# R7FA8D1BH register map
Vendor: Renesas; Series: RA8; File version: 1.2
CPU: CM85 r0p0, little endian, MPU, FPU, VTOR, 4 interrupt priority bits
Registers are 32-bit, read-write, reset 0x0 unless marked. A register's access mark holds for its fields unless they carry their own. Offsets are from the block's base; [hi:lo] are bit positions; {n}, {i} and the like mark numbered series; 'fields as' and 'values as' point back to an identical list.

## I3C (part 1 of 4) — I2C I3C unified IP
Base 0x4035F000
Same registers: I3C_NS 0x5035F000
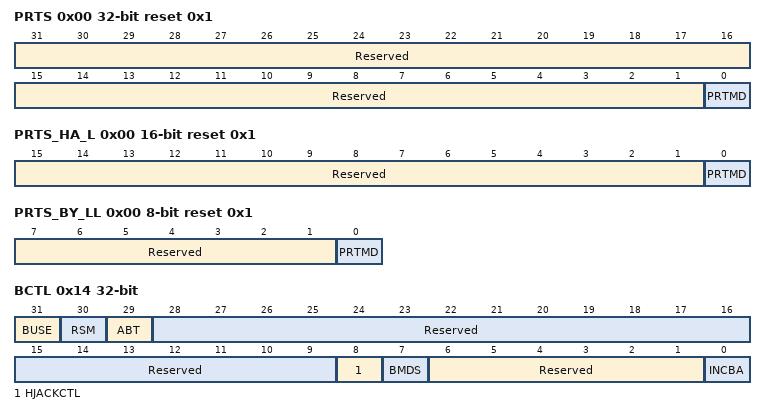
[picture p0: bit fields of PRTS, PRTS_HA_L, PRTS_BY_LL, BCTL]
0x00 PRTS reset 0x1 — Protocol Selection Register
  [31:1] Reserved — These bits are read as 0000000000000000000000000000000. The write value should be 0000000000000000000000000000000.
  [0] PRTMD — Protocol Mode.
    0=I3C Protocol mode; 1=I2C Protocol mode
0x00 PRTS_HA_L 16-bit reset 0x1 — Protocol Selection Register
  [15:1] Reserved — These bits are read as 000000000000000. The write value should be 000000000000000.
  [0] PRTMD — Protocol Mode.
    0=I3C Protocol mode; 1=I2C Protocol mode
0x00 PRTS_BY_LL 8-bit reset 0x1 — Protocol Selection Register
  [7:1] Reserved — These bits are read as 0000000. The write value should be 0000000.
  [0] PRTMD — Protocol Mode.
    0=I3C Protocol mode; 1=I2C Protocol mode
0x14 BCTL — Bus Control Register
  [31] BUSE read-modifies — Bus Enable
    0=This IP bus operation is Disabled; 1=This IP bus operation is Enabled
  [30] RSM write-1-clears read-modifies — Resume Values when read:
    0=This IP is Running; 1=This IP is Suspended (RW1C)
  [29] ABT — Abort
    0=This IP is Running; 1=This IP has Aborted a transfer
  [28:9] Reserved — These bits are read as 00000000000000000000. The write value should be 00000000000000000000.
  [8] HJACKCTL — Hot-Join Acknowledge Control
    0=ACK the Hot-Join request; 1=NACK and send broadcast CCC to disable Hot-Join
  [7] BMDS — Bus Mode Selection
    0=Legacy inclusive Bus mode disabled; 1=Legacy inclusive (mix) Bus mode enabled
  [6:1] Reserved — These bits are read as 000000. The write value should be 000000.
  [0] INCBA — Include I3C Broadcast Address
    0=Do not include I3C Broadcast Address for Private Transfers; 1=Include I3C Broadcast Address for Private Transfers
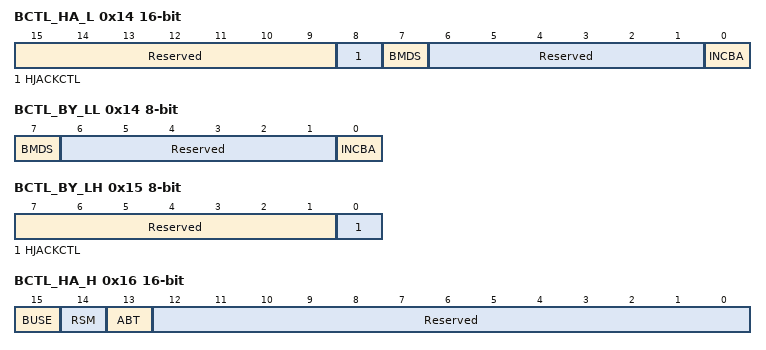
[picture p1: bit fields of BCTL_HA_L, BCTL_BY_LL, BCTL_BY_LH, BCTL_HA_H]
0x14 BCTL_HA_L 16-bit — Bus Control Register
  [15:9] Reserved — These bits are read as 0000000. The write value should be 0000000.
  [8] HJACKCTL — Hot-Join Acknowledge Control
    values as BCTL.HJACKCTL
  [7] BMDS — Bus Mode Selection
    values as BCTL.BMDS
  [6:1] Reserved — These bits are read as 000000. The write value should be 000000.
  [0] INCBA — Include I3C Broadcast Address
    values as BCTL.INCBA
0x14 BCTL_BY_LL 8-bit — Bus Control Register
  [7] BMDS — Bus Mode Selection
    values as BCTL.BMDS
  [6:1] Reserved — These bits are read as 000000. The write value should be 000000.
  [0] INCBA — Include I3C Broadcast Address
    values as BCTL.INCBA
0x15 BCTL_BY_LH 8-bit — Bus Control Register
  [7:1] Reserved — These bits are read as 0000000. The write value should be 0000000.
  [0] HJACKCTL — Hot-Join Acknowledge Control
    values as BCTL.HJACKCTL
0x16 BCTL_HA_H 16-bit — Bus Control Register
  [15] BUSE read-modifies — Bus Enable
    values as BCTL.BUSE
  [14] RSM write-1-clears read-modifies — Resume Values when read:
    0=This IP is Running; 1=This IP is Suspended (RW1C)
  [13] ABT — Abort
    0=This IP is Running; 1=This IP has Aborted a transfer
  [12:0] Reserved — These bits are read as 0000000000000. The write value should be 0000000000000.
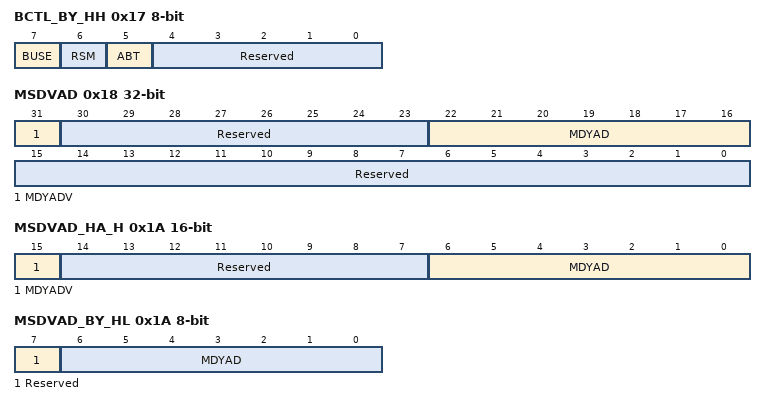
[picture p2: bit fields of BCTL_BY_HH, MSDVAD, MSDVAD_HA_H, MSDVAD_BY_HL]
0x17 BCTL_BY_HH 8-bit — Bus Control Register
  [7] BUSE read-modifies — Bus Enable
    values as BCTL.BUSE
  [6] RSM write-1-clears read-modifies — Resume Values when read:
    0=This IP is Running; 1=This IP is Suspended (RW1C)
  [5] ABT — Abort
    0=This IP is Running; 1=This IP has Aborted a transfer
  [4:0] Reserved — These bits are read as 00000. The write value should be 00000.
0x18 MSDVAD — Master Device Address Register
  [31] MDYADV — Master Dynamic Address Valid
    0=The Master Dynamic Address field is not valid; 1=The Master Dynamic Address Field is valid
  [30:23] Reserved — These bits are read as 00000000. The write value should be 00000000.
  [22:16] MDYAD — Master Dynamic Address
  [15:0] Reserved — These bits are read as 0000000000000000. The write value should be 0000000000000000.
0x1A MSDVAD_HA_H 16-bit — Master Device Address Register
  [15] MDYADV — Master Dynamic Address Valid
    values as MSDVAD.MDYADV
  [14:7] Reserved — These bits are read as 00000000. The write value should be 00000000.
  [6:0] MDYAD — Master Dynamic Address
0x1A MSDVAD_BY_HL 8-bit — Master Device Address Register
  [7] Reserved — This bit is read as 0. The write value should be 0.
  [6:0] MDYAD — Master Dynamic Address
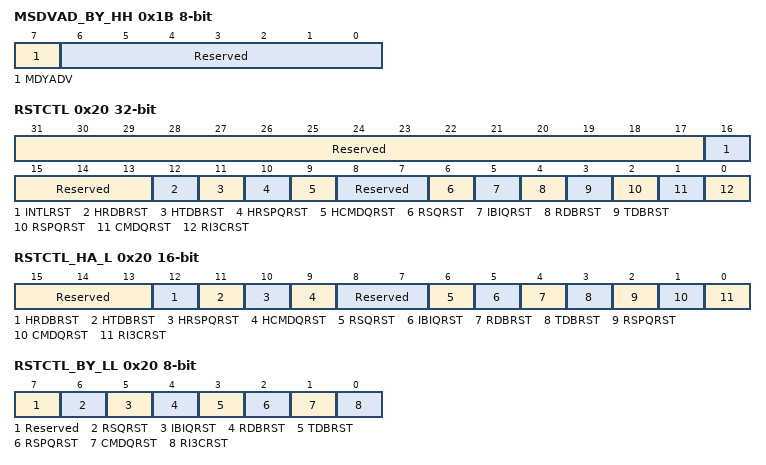
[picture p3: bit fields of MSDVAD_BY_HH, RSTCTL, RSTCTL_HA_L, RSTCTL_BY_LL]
0x1B MSDVAD_BY_HH 8-bit — Master Device Address Register
  [7] MDYADV — Master Dynamic Address Valid
    values as MSDVAD.MDYADV
  [6:0] Reserved — These bits are read as 0000000. The write value should be 0000000.
0x20 RSTCTL — Reset Control Register
  [31:17] Reserved — These bits are read as 000000000000000. The write value should be 000000000000000.
  [16] INTLRST — Internal Software Reset
    0=Releases of some registers and internal state; 1=Resets of some registers and internal state
  [15:13] Reserved — These bits are read as 000. The write value should be 000.
  [12] HRDBRST wo — High Priority Rx DATA Buffer Software Reset
    0=The High Priority Receive Queues in this IP do not flush; 1=The High Priority Receive Queues in this IP flush
  [11] HTDBRST wo — High Priority Tx DATA Buffer Software Reset
    0=The High Priority Transmit Queues in this IP do not flush; 1=The High Priority Transmit Queues in this IP flush
  [10] HRSPQRST wo — High Priority Response Queue Software Reset
    0=The High Priority Response Queues in this IP do not flush; 1=The High Priority Response Queues in this IP flush
  [9] HCMDQRST wo — High Priority Command Queue Software Reset
    0=The High Priority Command Queues in this IP do not flush; 1=The High Priority Command Queues in this IP flush
  [8:7] Reserved — These bits are read as 00. The write value should be 00.
  [6] RSQRST wo — Receive Status Queue Software Reset
    0=The Receive Status Queue in this IP do not flush; 1=The Receive Status Queue in this IP flush
  [5] IBIQRST wo — IBI Queue Software Reset
    0=The IBI Queues in this IP do not flush; 1=The IBI Queues in this IP flush
  [4] RDBRST wo — Rx DATA Buffer Software Reset
    0=The Receive Queues in this IP do not flush; 1=The Receive Queues in this IP flush
  [3] TDBRST wo — Tx DATA Buffer Software Reset
    0=The Transmit Queues in this IP do not flush; 1=The Transmit Queues in this IP flush
  [2] RSPQRST wo — Response Queue Software Reset
    0=The Response Queues in this IP do not flush; 1=The Response Queues in this IP flush
  [1] CMDQRST wo — Command Queue Software Reset
    0=The Command Queues in this IP do not flush; 1=The Command Queues in this IP flush
  [0] RI3CRST read-modifies — R-I3C Software Reset
    1=Reset of All registers and Internal State; 0=Releases of All registers and Internal State
0x20 RSTCTL_HA_L 16-bit — Reset Control Register
  [15:13] Reserved — These bits are read as 000. The write value should be 000.
  [12] HRDBRST wo — High Priority Rx DATA Buffer Software Reset
    values as RSTCTL.HRDBRST
  [11] HTDBRST wo — High Priority Tx DATA Buffer Software Reset
    values as RSTCTL.HTDBRST
  [10] HRSPQRST wo — High Priority Response Queue Software Reset
    values as RSTCTL.HRSPQRST
  [9] HCMDQRST wo — High Priority Command Queue Software Reset
    values as RSTCTL.HCMDQRST
  [8:7] Reserved — These bits are read as 00. The write value should be 00.
  [6] RSQRST wo — Receive Status Queue Software Reset
    values as RSTCTL.RSQRST
  [5] IBIQRST wo — IBI Queue Software Reset
    values as RSTCTL.IBIQRST
  [4] RDBRST wo — Rx DATA Buffer Software Reset
    values as RSTCTL.RDBRST
  [3] TDBRST wo — Tx DATA Buffer Software Reset
    values as RSTCTL.TDBRST
  [2] RSPQRST wo — Response Queue Software Reset
    values as RSTCTL.RSPQRST
  [1] CMDQRST wo — Command Queue Software Reset
    values as RSTCTL.CMDQRST
  [0] RI3CRST read-modifies — R-I3C Software Reset
    values as RSTCTL.RI3CRST
0x20 RSTCTL_BY_LL 8-bit — Reset Control Register
  [7] Reserved — This bit is read as 0. The write value should be 0.
  [6] RSQRST wo — Receive Status Queue Software Reset
    values as RSTCTL.RSQRST
  [5] IBIQRST wo — IBI Queue Software Reset
    values as RSTCTL.IBIQRST
  [4] RDBRST wo — Rx DATA Buffer Software Reset
    values as RSTCTL.RDBRST
  [3] TDBRST wo — Tx DATA Buffer Software Reset
    values as RSTCTL.TDBRST
  [2] RSPQRST wo — Response Queue Software Reset
    values as RSTCTL.RSPQRST
  [1] CMDQRST wo — Command Queue Software Reset
    values as RSTCTL.CMDQRST
  [0] RI3CRST read-modifies — R-I3C Software Reset
    values as RSTCTL.RI3CRST
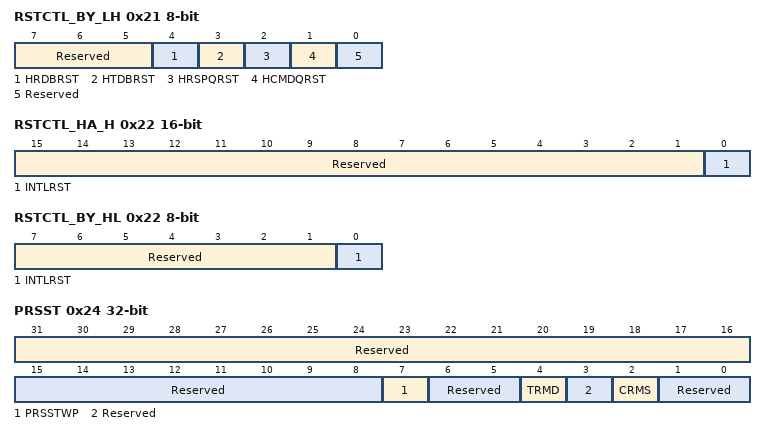
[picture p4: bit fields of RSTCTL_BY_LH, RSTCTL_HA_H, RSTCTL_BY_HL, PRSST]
0x21 RSTCTL_BY_LH 8-bit — Reset Control Register
  [7:5] Reserved — These bits are read as 000. The write value should be 000.
  [4] HRDBRST wo — High Priority Rx DATA Buffer Software Reset
    values as RSTCTL.HRDBRST
  [3] HTDBRST wo — High Priority Tx DATA Buffer Software Reset
    values as RSTCTL.HTDBRST
  [2] HRSPQRST wo — High Priority Response Queue Software Reset
    values as RSTCTL.HRSPQRST
  [1] HCMDQRST wo — High Priority Command Queue Software Reset
    values as RSTCTL.HCMDQRST
  [0] Reserved — This bit is read as 0. The write value should be 0.
0x22 RSTCTL_HA_H 16-bit — Reset Control Register
  [15:1] Reserved — These bits are read as 000000000000000. The write value should be 000000000000000.
  [0] INTLRST — Internal Software Reset
    values as RSTCTL.INTLRST
0x22 RSTCTL_BY_HL 8-bit — Reset Control Register
  [7:1] Reserved — These bits are read as 0000000. The write value should be 0000000.
  [0] INTLRST — Internal Software Reset
    values as RSTCTL.INTLRST
0x24 PRSST — Present State Register
  [31:16] Reserved — These bits are read as 0000000000000000. The write value should be 0000000000000000.
  [15:8] Reserved — These bits are read as 00000000. The write value should be 00000000.
  [7] PRSSTWP wo — Present State Write Protect
    0=Bit CRMS is protected; 1=Bit CRMS can be written (When writing simultaneously with the value of the target bit)
  [6:5] Reserved — These bits are read as 00. The write value should be 00.
  [4] TRMD ro — Transmit/Receive Mode
    0=Receive mode; 1=Transmit mode
  [3] Reserved — This bit is read as 0. The write value should be 0.
  [2] CRMS read-modifies — Current Master
    0=The Master is not the Current Master, and must request and acquire Bus ownership before initiating any transfer; 1=The Master is the Current Master, and as a result can initiate transfers
  [1:0] Reserved — These bits are read as 00. The write value should be 00.
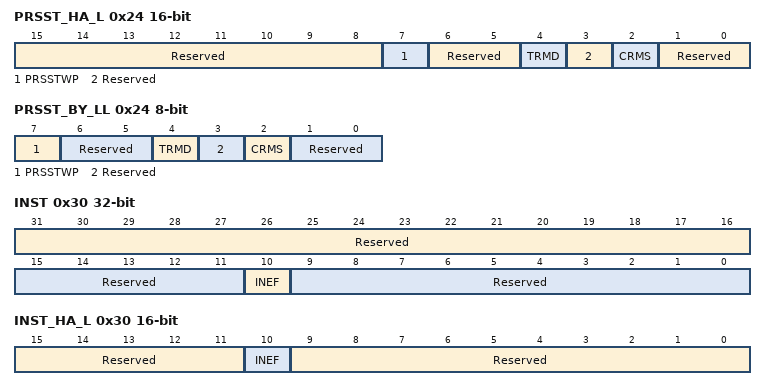
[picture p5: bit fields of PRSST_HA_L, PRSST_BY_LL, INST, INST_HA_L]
0x24 PRSST_HA_L 16-bit — Present State Register
  [15:8] Reserved — These bits are read as 00000000. The write value should be 00000000.
  [7] PRSSTWP wo — Present State Write Protect
    values as PRSST.PRSSTWP
  [6:5] Reserved — These bits are read as 00. The write value should be 00.
  [4] TRMD ro — Transmit/Receive Mode
    0=Receive mode; 1=Transmit mode
  [3] Reserved — This bit is read as 0. The write value should be 0.
  [2] CRMS read-modifies — Current Master
    values as PRSST.CRMS
  [1:0] Reserved — These bits are read as 00. The write value should be 00.
0x24 PRSST_BY_LL 8-bit — Present State Register
  [7] PRSSTWP wo — Present State Write Protect
    values as PRSST.PRSSTWP
  [6:5] Reserved — These bits are read as 00. The write value should be 00.
  [4] TRMD ro — Transmit/Receive Mode
    0=Receive mode; 1=Transmit mode
  [3] Reserved — This bit is read as 0. The write value should be 0.
  [2] CRMS read-modifies — Current Master
    values as PRSST.CRMS
  [1:0] Reserved — These bits are read as 00. The write value should be 00.
0x30 INST read-modifies — Internal Status Register
  [31:16] Reserved — These bits are read as 0000000000000000. The write value should be 0000000000000000.
  [15:11] Reserved — These bits are read as 00000. The write value should be 00000.
  [10] INEF read-modifies — Internal Error Flag
    0=This IP Internal Error has not detected; 1=This IP Internal Error has detected
  [9:0] Reserved — These bits are read as 0000000000. The write value should be 0000000000.
0x30 INST_HA_L 16-bit read-modifies — Internal Status Register
  [15:11] Reserved — These bits are read as 00000. The write value should be 00000.
  [10] INEF read-modifies — Internal Error Flag
    values as INST.INEF
  [9:0] Reserved — These bits are read as 0000000000. The write value should be 0000000000.
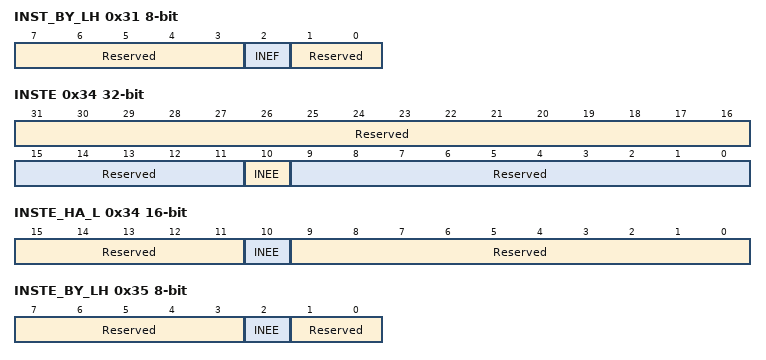
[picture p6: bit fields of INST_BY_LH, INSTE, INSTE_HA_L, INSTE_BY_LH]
0x31 INST_BY_LH 8-bit read-modifies — Internal Status Register
  [7:3] Reserved — These bits are read as 00000. The write value should be 00000.
  [2] INEF read-modifies — Internal Error Flag
    values as INST.INEF
  [1:0] Reserved — These bits are read as 00. The write value should be 00.
0x34 INSTE — Internal Status Enable Register
  [31:16] Reserved — These bits are read as 0000000000000000. The write value should be 0000000000000000.
  [15:11] Reserved — These bits are read as 00000. The write value should be 00000.
  [10] INEE — Internal Error Enable
    0=Disable INST.INEF; 1=Enable INST.INEF
  [9:0] Reserved — These bits are read as 0000000000. The write value should be 0000000000.
0x34 INSTE_HA_L 16-bit — Internal Status Enable Register
  [15:11] Reserved — These bits are read as 00000. The write value should be 00000.
  [10] INEE — Internal Error Enable
    0=Disable INST.INEF; 1=Enable INST.INEF
  [9:0] Reserved — These bits are read as 0000000000. The write value should be 0000000000.
0x35 INSTE_BY_LH 8-bit — Internal Status Enable Register
  [7:3] Reserved — These bits are read as 00000. The write value should be 00000.
  [2] INEE — Internal Error Enable
    0=Disable INST.INEF; 1=Enable INST.INEF
  [1:0] Reserved — These bits are read as 00. The write value should be 00.
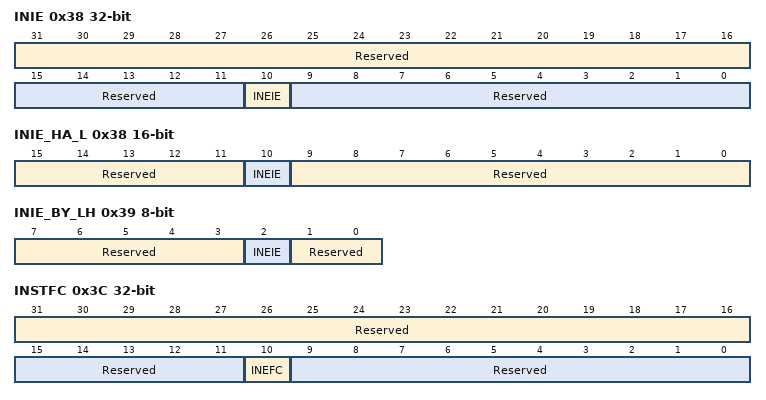
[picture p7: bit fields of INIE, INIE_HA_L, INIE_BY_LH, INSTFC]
0x38 INIE — Internal Interrupt Enable Register
  [31:16] Reserved — These bits are read as 0000000000000000. The write value should be 0000000000000000.
  [15:11] Reserved — These bits are read as 00000. The write value should be 00000.
  [10] INEIE — Internal Error Interrupt Enable
    0=Disables Non-recoverable Internal Error Interrupt Signal; 1=Enables Non-recoverable Internal Error Interrupt Signal
  [9:0] Reserved — These bits are read as 0000000000. The write value should be 0000000000.
0x38 INIE_HA_L 16-bit — Internal Interrupt Enable Register
  [15:11] Reserved — These bits are read as 00000. The write value should be 00000.
  [10] INEIE — Internal Error Interrupt Enable
    values as INIE.INEIE
  [9:0] Reserved — These bits are read as 0000000000. The write value should be 0000000000.
0x39 INIE_BY_LH 8-bit — Internal Interrupt Enable Register
  [7:3] Reserved — These bits are read as 00000. The write value should be 00000.
  [2] INEIE — Internal Error Interrupt Enable
    values as INIE.INEIE
  [1:0] Reserved — These bits are read as 00. The write value should be 00.
0x3C INSTFC wo — Internal Status Force Register
  [31:16] Reserved — The write value should be 0000000000000000.
  [15:11] Reserved — The write value should be 00000.
  [10] INEFC — Internal Error Force
    0=not force a specific interrupt; 1=force a specific interrupt
  [9:0] Reserved — The write value should be 0000000000.
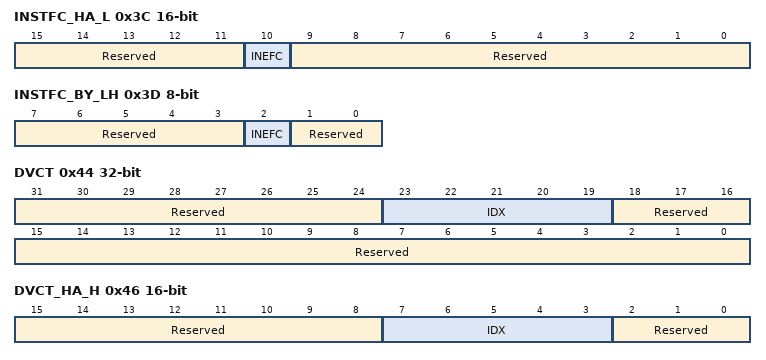
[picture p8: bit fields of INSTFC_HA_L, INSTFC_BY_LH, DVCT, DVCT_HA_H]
0x3C INSTFC_HA_L 16-bit wo — Internal Status Force Register
  [15:11] Reserved — The write value should be 00000.
  [10] INEFC — Internal Error Force
    values as INSTFC.INEFC
  [9:0] Reserved — The write value should be 0000000000.
0x3D INSTFC_BY_LH 8-bit wo — Internal Status Force Register
  [7:3] Reserved — The write value should be 00000.
  [2] INEFC — Internal Error Force
    values as INSTFC.INEFC
  [1:0] Reserved — The write value should be 00.
0x44 DVCT ro — Device Characteristic Table Register
  [31:24] Reserved — These bits are read as 00000000.
  [23:19] IDX — DCT Table Index
  [18:0] Reserved — These bits are read as 0000000000000000000.
0x46 DVCT_HA_H 16-bit ro — Device Characteristic Table Register
  [15:8] Reserved — These bits are read as 00000000.
  [7:3] IDX — DCT Table Index
  [2:0] Reserved — These bits are read as 000.
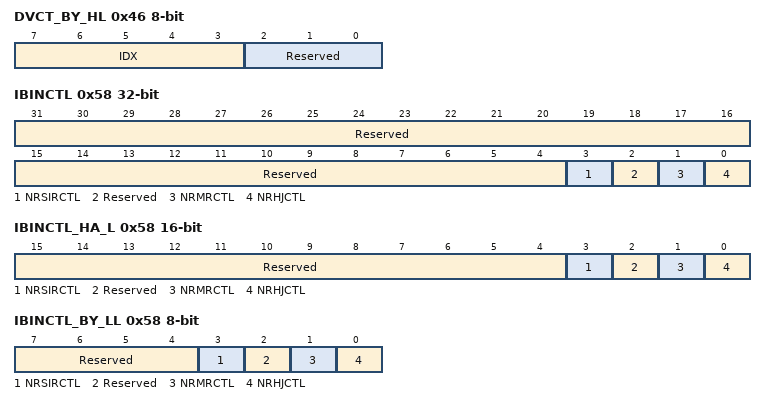
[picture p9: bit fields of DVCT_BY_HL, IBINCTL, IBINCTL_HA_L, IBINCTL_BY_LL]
0x46 DVCT_BY_HL 8-bit ro — Device Characteristic Table Register
  [7:3] IDX — DCT Table Index
  [2:0] Reserved — These bits are read as 000.
0x58 IBINCTL — IBI Notify Control Register
  [31:4] Reserved — These bits are read as 0000000000000000000000000000. The write value should be 0000000000000000000000000000.
  [3] NRSIRCTL — Notify Rejected Slave Interrupt Request Control
    0=Do not pass rejected IBI Status to the IBI Queue/Rings, if the incoming SIR is NACKed and is auto-disabled based on DVSIRRJ field in relevant DAT entry; 1=Pass rejected IBI Status to the IBI Queue/Rings, if the incoming SIR is NACKed and is auto-disabled based on DVSIRRJ field in relevant DAT entry
  [2] Reserved — This bit is read as 0. The write value should be 0.
  [1] NRMRCTL — Notify Rejected Master Request Control
    0=Do not pass rejected IBI Status to IBI Queue/Ring, if the incoming Master Request is NACKed and is auto-disabled based on DVMRRJ field in relevant DAT entry; 1=Pass rejected IBI Status to the IBI Queue, if the incoming Master Request is NACKed and is auto-disabled based on DVMRRJ field in relevant DAT entry
  [0] NRHJCTL — Notify Rejected Hot-Join Control
    0=Do not pass rejected IBI Status to IBI Queue, if the incoming HotJoin request is NACKed and is auto-disabled based on field HJACKCTL of BCTL; 1=Pass rejected IBI Status to the IBI Queue, if the incoming Hot Join request is NACKed and is auto-disabled based on field HJACKCTL of BCTL
0x58 IBINCTL_HA_L 16-bit — IBI Notify Control Register
  [15:4] Reserved — These bits are read as 000000000000. The write value should be 000000000000.
  [3] NRSIRCTL — Notify Rejected Slave Interrupt Request Control
    values as IBINCTL.NRSIRCTL
  [2] Reserved — This bit is read as 0. The write value should be 0.
  [1] NRMRCTL — Notify Rejected Master Request Control
    values as IBINCTL.NRMRCTL
  [0] NRHJCTL — Notify Rejected Hot-Join Control
    values as IBINCTL.NRHJCTL
0x58 IBINCTL_BY_LL 8-bit — IBI Notify Control Register
  [7:4] Reserved — These bits are read as 0000. The write value should be 0000.
  [3] NRSIRCTL — Notify Rejected Slave Interrupt Request Control
    values as IBINCTL.NRSIRCTL
  [2] Reserved — This bit is read as 0. The write value should be 0.
  [1] NRMRCTL — Notify Rejected Master Request Control
    values as IBINCTL.NRMRCTL
  [0] NRHJCTL — Notify Rejected Hot-Join Control
    values as IBINCTL.NRHJCTL
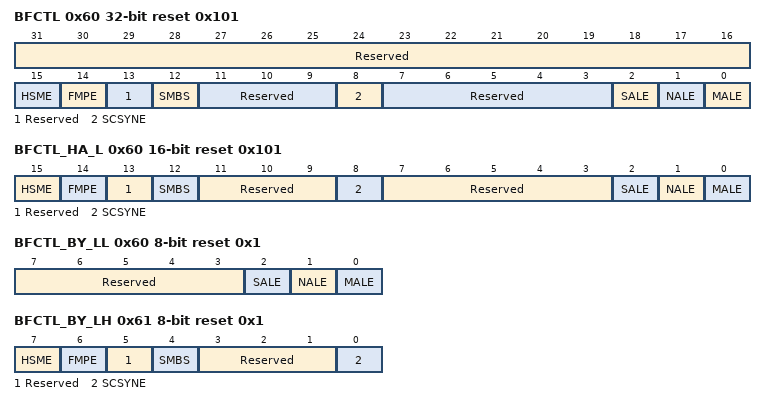
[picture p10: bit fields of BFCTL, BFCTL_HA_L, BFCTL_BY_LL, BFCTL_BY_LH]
0x60 BFCTL reset 0x101 — Bus Function Control Register
  [31:16] Reserved — These bits are read as 0000000000000000. The write value should be 0000000000000000.
  [15] HSME — High Speed Mode Enable
    0=Disable High Speed Mode; 1=Enable High Speed Mode
  [14] FMPE — Fast-mode Plus Enable
    0=No Fm+ slope control circuit uses for the SCLn pin and SDAn pin; 1=An Fm+ slope control circuit uses for the SCLn pin and SDAn pin
  [13] Reserved — This bit is read as 0. The write value should be 0.
  [12] SMBS — SMBus/I2C Bus Selection
    0=The I2C bus select; 1=The SMBus select
  [11:9] Reserved — These bits are read as 000. The write value should be 000.
  [8] SCSYNE — SCL Synchronous Circuit Enable
    0=No SCL synchronous circuit uses; 1=An SCL synchronous circuit uses
  [7:3] Reserved — These bits are read as 00000. The write value should be 00000.
  [2] SALE — Slave Arbitration-Lost Detection Enable
    0=Slave arbitration-lost detection disables; 1=Slave arbitration-lost detection enables
  [1] NALE — NACK Transmission Arbitration-Lost Detection Enable
    0=NACK transmission arbitration-lost detection disables; 1=NACK transmission arbitration-lost detection enables
  [0] MALE — Master Arbitration-Lost Detection Enable
    0=Master arbitration-lost detection disables; 1=Master arbitration-lost detection enables
0x60 BFCTL_HA_L 16-bit reset 0x101 — Bus Function Control Register
  [15] HSME — High Speed Mode Enable
    0=Disable High Speed Mode; 1=Enable High Speed Mode
  [14] FMPE — Fast-mode Plus Enable
    values as BFCTL.FMPE
  [13] Reserved — This bit is read as 0. The write value should be 0.
  [12] SMBS — SMBus/I2C Bus Selection
    0=The I2C bus select; 1=The SMBus select
  [11:9] Reserved — These bits are read as 000. The write value should be 000.
  [8] SCSYNE — SCL Synchronous Circuit Enable
    values as BFCTL.SCSYNE
  [7:3] Reserved — These bits are read as 00000. The write value should be 00000.
  [2] SALE — Slave Arbitration-Lost Detection Enable
    values as BFCTL.SALE
  [1] NALE — NACK Transmission Arbitration-Lost Detection Enable
    values as BFCTL.NALE
  [0] MALE — Master Arbitration-Lost Detection Enable
    values as BFCTL.MALE
0x60 BFCTL_BY_LL 8-bit reset 0x1 — Bus Function Control Register
  [7:3] Reserved — These bits are read as 00000. The write value should be 00000.
  [2] SALE — Slave Arbitration-Lost Detection Enable
    values as BFCTL.SALE
  [1] NALE — NACK Transmission Arbitration-Lost Detection Enable
    values as BFCTL.NALE
  [0] MALE — Master Arbitration-Lost Detection Enable
    values as BFCTL.MALE
0x61 BFCTL_BY_LH 8-bit reset 0x1 — Bus Function Control Register
  [7] HSME — High Speed Mode Enable
    0=Disable High Speed Mode; 1=Enable High Speed Mode
  [6] FMPE — Fast-mode Plus Enable
    values as BFCTL.FMPE
  [5] Reserved — This bit is read as 0. The write value should be 0.
  [4] SMBS — SMBus/I2C Bus Selection
    0=The I2C bus select; 1=The SMBus select
  [3:1] Reserved — These bits are read as 000. The write value should be 000.
  [0] SCSYNE — SCL Synchronous Circuit Enable
    values as BFCTL.SCSYNE
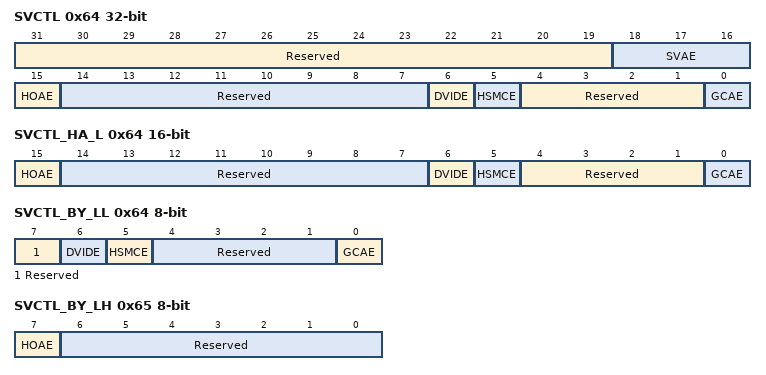
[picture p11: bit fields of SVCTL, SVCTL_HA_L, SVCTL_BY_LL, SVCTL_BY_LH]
0x64 SVCTL — Slave Control Register
  [31:19] Reserved — These bits are read as 0000000000000. The write value should be 0000000000000.
  [18:16] SVAE — Slave Address Enable $x ($x=2 to 0)
    0=Slave $x disables; 1=Slave $x enables
  [15] HOAE — Host Address Enable
    0=Host address detection disables; 1=Host address detection enables
  [14:7] Reserved — These bits are read as 00000000. The write value should be 00000000.
  [6] DVIDE — Device-ID Address Enable
    0=Device-ID address detection disables; 1=Device-ID address detection enables
  [5] HSMCE — Hs-mode Master Code Enable
    0=Hs-mode Master Code Detection disables; 1=Hs-mode Master Code Detection enables
  [4:1] Reserved — These bits are read as 0000. The write value should be 0000.
  [0] GCAE — General Call Address Enable
    0=General call address detection disables; 1=General call address detection enables
0x64 SVCTL_HA_L 16-bit — Slave Control Register
  [15] HOAE — Host Address Enable
    values as SVCTL.HOAE
  [14:7] Reserved — These bits are read as 00000000. The write value should be 00000000.
  [6] DVIDE — Device-ID Address Enable
    values as SVCTL.DVIDE
  [5] HSMCE — Hs-mode Master Code Enable
    values as SVCTL.HSMCE
  [4:1] Reserved — These bits are read as 0000. The write value should be 0000.
  [0] GCAE — General Call Address Enable
    values as SVCTL.GCAE
0x64 SVCTL_BY_LL 8-bit — Slave Control Register
  [7] Reserved — This bit is read as 0. The write value should be 0.
  [6] DVIDE — Device-ID Address Enable
    values as SVCTL.DVIDE
  [5] HSMCE — Hs-mode Master Code Enable
    values as SVCTL.HSMCE
  [4:1] Reserved — These bits are read as 0000. The write value should be 0000.
  [0] GCAE — General Call Address Enable
    values as SVCTL.GCAE
0x65 SVCTL_BY_LH 8-bit — Slave Control Register
  [7] HOAE — Host Address Enable
    values as SVCTL.HOAE
  [6:0] Reserved — These bits are read as 0000000. The write value should be 0000000.
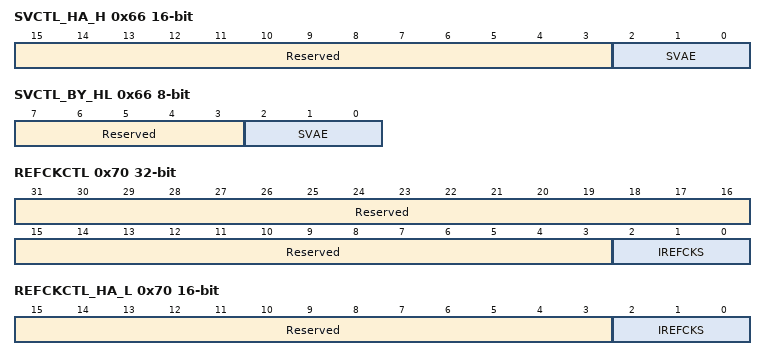
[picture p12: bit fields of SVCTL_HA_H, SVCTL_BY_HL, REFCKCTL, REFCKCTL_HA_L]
0x66 SVCTL_HA_H 16-bit — Slave Control Register
  [15:3] Reserved — These bits are read as 0000000000000. The write value should be 0000000000000.
  [2:0] SVAE — Slave Address Enable $x ($x=2 to 0)
    0=Slave $x disables; 1=Slave $x enables
0x66 SVCTL_BY_HL 8-bit — Slave Control Register
  [7:3] Reserved — These bits are read as 00000. The write value should be 00000.
  [2:0] SVAE — Slave Address Enable $x ($x=2 to 0)
    0=Slave $x disables; 1=Slave $x enables
0x70 REFCKCTL — Reference Clock Control Register
  [31:3] Reserved — These bits are read as 00000000000000000000000000000. The write value should be 00000000000000000000000000000.
  [2:0] IREFCKS — Internal Reference Clock SelectionSelects the internal reference clock source (I3Cφ) for this IP.
    0=TCLK/1 clock; 1=TCLK/2 clock; 2=TCLK/4 clock; 3=TCLK/8 clock; 4=TCLK/16 clock; 5=TCLK/32 clock; 6=TCLK/64 clock; 7=TCLK/128 clock
0x70 REFCKCTL_HA_L 16-bit — Reference Clock Control Register
  [15:3] Reserved — These bits are read as 0000000000000. The write value should be 0000000000000.
  [2:0] IREFCKS — Internal Reference Clock SelectionSelects the internal reference clock source (I3Cφ) for this IP.
    values as REFCKCTL.IREFCKS
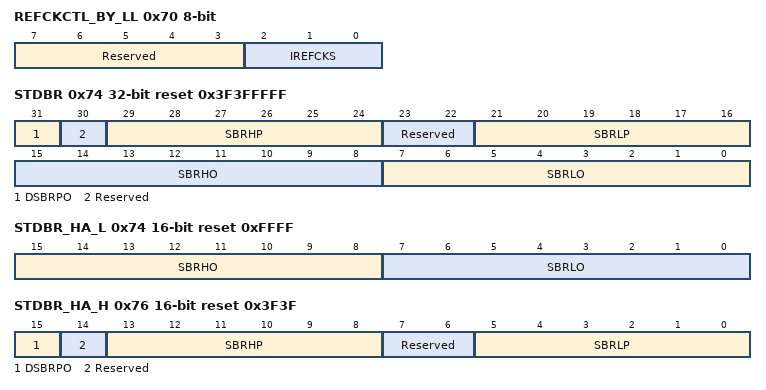
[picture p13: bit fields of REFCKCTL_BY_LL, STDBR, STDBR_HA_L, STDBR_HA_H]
0x70 REFCKCTL_BY_LL 8-bit — Reference Clock Control Register
  [7:3] Reserved — These bits are read as 00000. The write value should be 00000.
  [2:0] IREFCKS — Internal Reference Clock SelectionSelects the internal reference clock source (I3Cφ) for this IP.
    values as REFCKCTL.IREFCKS
0x74 STDBR reset 0x3F3FFFFF — Standard Bit Rate Register
  [31] DSBRPO — Double the Standard Bit Rate Period for Open-Drain
    0=Normal
  [30] Reserved — This bit is read as 0. The write value should be 0.
  [29:24] SBRHP — Standard Bit Rate High-Level Period Push-Pull
  [23:22] Reserved — These bits are read as 00. The write value should be 00.
  [21:16] SBRLP — Standard Bit Rate Low-Level Period Push-Pull
  [15:8] SBRHO — Standard Bit Rate High-Level Period Open-Drain
  [7:0] SBRLO — Standard Bit Rate Low-Level Period Open-Drain
0x74 STDBR_HA_L 16-bit reset 0xFFFF — Standard Bit Rate Register
  [15:8] SBRHO — Standard Bit Rate High-Level Period Open-Drain
  [7:0] SBRLO — Standard Bit Rate Low-Level Period Open-Drain
0x74 STDBR_BY_LL 8-bit reset 0xFF — Standard Bit Rate Register
  [7:0] SBRLO — Standard Bit Rate Low-Level Period Open-Drain
0x75 STDBR_BY_LH 8-bit reset 0xFF — Standard Bit Rate Register
  [7:0] SBRHO — Standard Bit Rate High-Level Period Open-Drain
0x76 STDBR_HA_H 16-bit reset 0x3F3F — Standard Bit Rate Register
  [15] DSBRPO — Double the Standard Bit Rate Period for Open-Drain
    0=Normal
  [14] Reserved — This bit is read as 0. The write value should be 0.
  [13:8] SBRHP — Standard Bit Rate High-Level Period Push-Pull
  [7:6] Reserved — These bits are read as 00. The write value should be 00.
  [5:0] SBRLP — Standard Bit Rate Low-Level Period Push-Pull
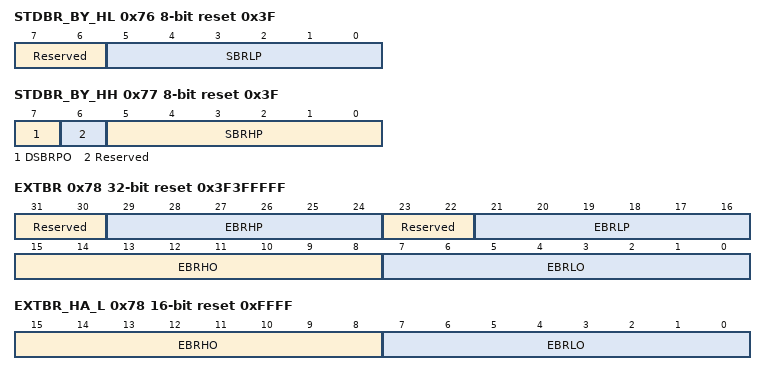
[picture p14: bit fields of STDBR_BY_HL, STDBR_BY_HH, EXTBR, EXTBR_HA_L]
0x76 STDBR_BY_HL 8-bit reset 0x3F — Standard Bit Rate Register
  [7:6] Reserved — These bits are read as 00. The write value should be 00.
  [5:0] SBRLP — Standard Bit Rate Low-Level Period Push-Pull
0x77 STDBR_BY_HH 8-bit reset 0x3F — Standard Bit Rate Register
  [7] DSBRPO — Double the Standard Bit Rate Period for Open-Drain
    0=Normal
  [6] Reserved — This bit is read as 0. The write value should be 0.
  [5:0] SBRHP — Standard Bit Rate High-Level Period Push-Pull
0x78 EXTBR reset 0x3F3FFFFF — Extended Bit Rate Register
  [31:30] Reserved — These bits are read as 00. The write value should be 00.
  [29:24] EBRHP — Extended Bit Rate Low-Level Period Push-Pull
  [23:22] Reserved — These bits are read as 00. The write value should be 00.
  [21:16] EBRLP — Extended Bit Rate Low-Level Period Push-Pull
  [15:8] EBRHO — Extended Bit Rate Low-Level Period Open-Drain
  [7:0] EBRLO — Extended Bit Rate Low-Level Period Open-Drain
0x78 EXTBR_HA_L 16-bit reset 0xFFFF — Extended Bit Rate Register
  [15:8] EBRHO — Extended Bit Rate Low-Level Period Open-Drain
  [7:0] EBRLO — Extended Bit Rate Low-Level Period Open-Drain
0x78 EXTBR_BY_LL 8-bit reset 0xFF — Extended Bit Rate Register
  [7:0] EBRLO — Extended Bit Rate Low-Level Period Open-Drain
0x79 EXTBR_BY_LH 8-bit reset 0xFF — Extended Bit Rate Register
  [7:0] EBRHO — Extended Bit Rate Low-Level Period Open-Drain
0x7A EXTBR_HA_H 16-bit reset 0xFFFF — Extended Bit Rate Register
  [15:14] Reserved — These bits are read as 11. The write value should be 11.
  [13:8] EBRHP — Extended Bit Rate Low-Level Period Push-Pull
  [7:6] Reserved — These bits are read as 11. The write value should be 11.
  [5:0] EBRLP — Extended Bit Rate Low-Level Period Push-Pull
0x7A EXTBR_BY_HL 8-bit reset 0xFF — Extended Bit Rate Register
  [7:6] Reserved — These bits are read as 11. The write value should be 11.
  [5:0] EBRLP — Extended Bit Rate Low-Level Period Push-Pull
0x7B EXTBR_BY_HH 8-bit reset 0xFF — Extended Bit Rate Register
  [7:6] Reserved — These bits are read as 11. The write value should be 11.
  [5:0] EBRHP — Extended Bit Rate Low-Level Period Push-Pull
0x7C BFRECDT — Bus Free Condition Detection Time Register
  [31:9] Reserved — These bits are read as 00000000000000000000000. The write value should be 00000000000000000000000.
  [8:0] FRECYC — Bus Free Condition Detection Cycle
0x7C BFRECDT_HA_L 16-bit — Bus Free Condition Detection Time Register
  [15:9] Reserved — These bits are read as 0000000. The write value should be 0000000.
  [8:0] FRECYC — Bus Free Condition Detection Cycle
0x7C BFRECDT_BY_LL 8-bit — Bus Free Condition Detection Time Register
  [7:0] FRECYC — Bus Free Condition Detection Cycle
0x7D BFRECDT_BY_LH 8-bit — Bus Free Condition Detection Time Register
  [7:1] Reserved — These bits are read as 0000000. The write value should be 0000000.
  [0] FRECYC — Bus Free Condition Detection Cycle
0x80 BAVLCDT — Bus Available Condition Detection Time Register
  [31:9] Reserved — These bits are read as 00000000000000000000000. The write value should be 00000000000000000000000.
  [8:0] AVLCYC — Bus Available Condition Detection Cycle
0x80 BAVLCDT_HA_L 16-bit — Bus Available Condition Detection Time Register
  [15:9] Reserved — These bits are read as 0000000. The write value should be 0000000.
  [8:0] AVLCYC — Bus Available Condition Detection Cycle
0x80 BAVLCDT_BY_LL 8-bit — Bus Available Condition Detection Time Register
  [7:0] AVLCYC — Bus Available Condition Detection Cycle
0x81 BAVLCDT_BY_LH 8-bit — Bus Available Condition Detection Time Register
  [7:1] Reserved — These bits are read as 0000000. The write value should be 0000000.
  [0] AVLCYC — Bus Available Condition Detection Cycle
0x84 BIDLCDT — Bus Idle Condition Detection Time Register
  [31:18] Reserved — These bits are read as 00000000000000. The write value should be 00000000000000.
  [17:0] IDLCYC — Bus Idle Condition Detection Cycle
0x84 BIDLCDT_HA_L 16-bit — Bus Idle Condition Detection Time Register
  [15:0] IDLCYC — Bus Idle Condition Detection Cycle
0x84 BIDLCDT_BY_LL 8-bit — Bus Idle Condition Detection Time Register
  [7:0] IDLCYC — Bus Idle Condition Detection Cycle
0x85 BIDLCDT_BY_LH 8-bit — Bus Idle Condition Detection Time Register
  [7:0] IDLCYC — Bus Idle Condition Detection Cycle
0x86 BIDLCDT_HA_H 16-bit — Bus Idle Condition Detection Time Register
  [15:2] Reserved — These bits are read as 00000000000000. The write value should be 00000000000000.
  [1:0] IDLCYC — Bus Idle Condition Detection Cycle
0x86 BIDLCDT_BY_HL 8-bit — Bus Idle Condition Detection Time Register
  [7:2] Reserved — These bits are read as 000000. The write value should be 000000.
  [1:0] IDLCYC — Bus Idle Condition Detection Cycle
0x88 OUTCTL reset 0x3 — Output Control Register
  [31:16] Reserved — These bits are read as 0000000000000000. The write value should be 0000000000000000.
  [15] SDODCS — SDA Output Delay Clock Source Selection
    0=The internal reference clock (I3Cφ) is selected as the clock source of the SDA output delay counter; 1=The internal reference clock divided by 2 (I3Cφ/2) is selected as the clock source of the SDA output delay counter. *1
  [14:11] Reserved — These bits are read as 0000. The write value should be 0000.
  [10:8] SDOD — SDA Output Delay
    0=No output delay; 1=1 I3Cφ cycle; {v}={v} I3Cφ cycles (v=2..7); 0=No output delay; 1=1 or 2 I3Cφ cycles; 2=3 or 4 I3Cφ cycles; 3=5 or 6 I3Cφ cycles; 4=7 or 8 I3Cφ cycles; 5=9 or 10 I3Cφ cycles; 6=11 or 12 I3Cφ cycles; 7=13 or 14 I3Cφ cycles
  [7:5] Reserved — These bits are read as 000. The write value should be 000.
  [4] EXCYC read-modifies — Extra SCL Clock Cycle Output
    0=Does not output an extra SCL clock cycle (default); 1=Outputs an extra SCL clock cycle; 0b=(The EXCYC bit is cleared automatically after one clock cycle is output.)
  [3] Reserved — This bit is read as 0. The write value should be 0.
  [2] SOCWP wo — SCL/SDA Output Control Write Protect
    0=Bits SCOC and SDOC are protected; 1=Bits SCOC and SDOC can be written (When writing simultaneously with the value of the target bit)
  [1] SCOC — SCL Output Control
    0=This IP drives the SCLn pin low; 1=This IP releases the SCLn pin
  [0] SDOC — SDA Output Control
    0=This IP drives the SDAn pin low; 1=This IP releases the SDAn pin
0x88 OUTCTL_HA_L 16-bit reset 0x3 — Output Control Register
  [15] SDODCS — SDA Output Delay Clock Source Selection
    values as OUTCTL.SDODCS
  [14:11] Reserved — These bits are read as 0000. The write value should be 0000.
  [10:8] SDOD — SDA Output Delay
    values as OUTCTL.SDOD
  [7:5] Reserved — These bits are read as 000. The write value should be 000.
  [4] EXCYC read-modifies — Extra SCL Clock Cycle Output
    values as OUTCTL.EXCYC
  [3] Reserved — This bit is read as 0. The write value should be 0.
  [2] SOCWP wo — SCL/SDA Output Control Write Protect
    values as OUTCTL.SOCWP
  [1] SCOC — SCL Output Control
    values as OUTCTL.SCOC
  [0] SDOC — SDA Output Control
    values as OUTCTL.SDOC
0x88 OUTCTL_BY_LL 8-bit reset 0x3 — Output Control Register
  [7:5] Reserved — These bits are read as 000. The write value should be 000.
  [4] EXCYC read-modifies — Extra SCL Clock Cycle Output
    values as OUTCTL.EXCYC
  [3] Reserved — This bit is read as 0. The write value should be 0.
  [2] SOCWP wo — SCL/SDA Output Control Write Protect
    values as OUTCTL.SOCWP
  [1] SCOC — SCL Output Control
    values as OUTCTL.SCOC
  [0] SDOC — SDA Output Control
    values as OUTCTL.SDOC
0x89 OUTCTL_BY_LH 8-bit — Output Control Register
  [7] SDODCS — SDA Output Delay Clock Source Selection
    values as OUTCTL.SDODCS
  [6:3] Reserved — These bits are read as 0000. The write value should be 0000.
  [2:0] SDOD — SDA Output Delay
    values as OUTCTL.SDOD
0x8C INCTL reset 0xD0 — Input Control Register
  [31:16] Reserved — These bits are read as 0000000000000000. The write value should be 0000000000000000.
  [15:8] Reserved — These bits are read as 00000000. The write value should be 00000000.
  [7:6] Reserved — These bits are read as 11. The write value should be 11.
  [5] Reserved — This bit is read as 0. The write value should be 0.
  [4] DNFE — Digital Noise Filter Circuit Enable
    0=No digital noise filter circuit is used; 1=A digital noise filter circuit is used
  [3:0] DNFS — Digital Noise Filter Stage Selection
    0=Noise of up to one I3Cφ cycle is filtered out (single-stage filter); 1=Noise of up to two I3Cφ cycles is filtered out (2-stage filter); 2=Noise of up to three I3Cφ cycles is filtered out (3-stage filter); 3=Noise of up to four I3Cφ cycles is filtered out (4-stage filter); 4=Noise of up to five I3Cφ cycles is filtered out (5-stage filter); 0b=……; 15=Noise of up to sixteen I3Cφ cycles is filtered out (16-stage filter)
0x8C INCTL_HA_L 16-bit reset 0xD0 — Input Control Register
  [15:8] Reserved — These bits are read as 00000000. The write value should be 00000000.
  [7:6] Reserved — These bits are read as 11. The write value should be 11.
  [5] Reserved — This bit is read as 0. The write value should be 0.
  [4] DNFE — Digital Noise Filter Circuit Enable
    values as INCTL.DNFE
  [3:0] DNFS — Digital Noise Filter Stage Selection
    values as INCTL.DNFS
0x8C INCTL_BY_LL 8-bit reset 0xD0 — Input Control Register
  [7:6] Reserved — These bits are read as 11. The write value should be 11.
  [5] Reserved — This bit is read as 0. The write value should be 0.
  [4] DNFE — Digital Noise Filter Circuit Enable
    values as INCTL.DNFE
  [3:0] DNFS — Digital Noise Filter Stage Selection
    values as INCTL.DNFS
0x90 TMOCTL reset 0x30 — Timeout Control Register
  [31:16] Reserved — These bits are read as 0000000000000000. The write value should be 0000000000000000.
  [15:8] Reserved — These bits are read as 00000000. The write value should be 00000000.
  [7:6] TOMDS — Timeout Operation Mode Selection
    0=Timeout is detected during the following conditions; 1=Timeout is detected while the bus is busy
  [5] TOHCTL — Timeout H Count Control
    0=Count is disabled while the SCLn line is at a high level; 1=Count is enabled while the SCLn line is at a high level
  [4] TOLCTL — Timeout L Count Control
    0=Count is disabled while the SCLn line is at a low level; 1=Count is enabled while the SCLn line is at a low level
  [3:2] Reserved — These bits are read as 00. The write value should be 00.
  [1:0] TODTS — Timeout Detection Time Selection
    0=16bit-timeout; 1=14bit-timeout; 2=8bit-timeout; 3=6bit-timeout
0x90 TMOCTL_HA_L 16-bit reset 0x30 — Timeout Control Register
  [15:8] Reserved — These bits are read as 00000000. The write value should be 00000000.
  [7:6] TOMDS — Timeout Operation Mode Selection
    values as TMOCTL.TOMDS
  [5] TOHCTL — Timeout H Count Control
    values as TMOCTL.TOHCTL
  [4] TOLCTL — Timeout L Count Control
    values as TMOCTL.TOLCTL
  [3:2] Reserved — These bits are read as 00. The write value should be 00.
  [1:0] TODTS — Timeout Detection Time Selection
    values as TMOCTL.TODTS
0x90 TMOCTL_BY_LL 8-bit reset 0x30 — Timeout Control Register
  [7:6] TOMDS — Timeout Operation Mode Selection
    values as TMOCTL.TOMDS
  [5] TOHCTL — Timeout H Count Control
    values as TMOCTL.TOHCTL
  [4] TOLCTL — Timeout L Count Control
    values as TMOCTL.TOLCTL
  [3:2] Reserved — These bits are read as 00. The write value should be 00.
  [1:0] TODTS — Timeout Detection Time Selection
    values as TMOCTL.TODTS
0x98 WUCTL reset 0x41 — Wake Up Unit Control Register
  [31:8] Reserved — These bits are read as 000000000000000000000000. The write value should be 000000000000000000000000.
  [7] WUFE — Wake Up function Enable
    0=Wake-up function disables; 1=Wake-up function enables
  [6] WUFSYNE — Wake-Up function Synchronous Enable
    0=This IP asynchronous circuit enable; 1=This IP synchronous circuit enable
  [5] Reserved — This bit is read as 0. The write value should be 0.
  [4] WUANFS — Wake-Up Analog Noise Filter Selection
    0=Do not add the Wake Up analog filter; 1=Add the Wake Up analog filter
  [3:1] Reserved — These bits are read as 000. The write value should be 000.
  [0] WUACKS — Wake-Up Acknowledge Selection
0x98 WUCTL_HA_L 16-bit reset 0x41 — Wake Up Unit Control Register
  [15:8] Reserved — These bits are read as 00000000. The write value should be 00000000.
  [7] WUFE — Wake Up function Enable
    0=Wake-up function disables; 1=Wake-up function enables
  [6] WUFSYNE — Wake-Up function Synchronous Enable
    values as WUCTL.WUFSYNE
  [5] Reserved — This bit is read as 0. The write value should be 0.
  [4] WUANFS — Wake-Up Analog Noise Filter Selection
    values as WUCTL.WUANFS
  [3:1] Reserved — These bits are read as 000. The write value should be 000.
  [0] WUACKS — Wake-Up Acknowledge Selection
